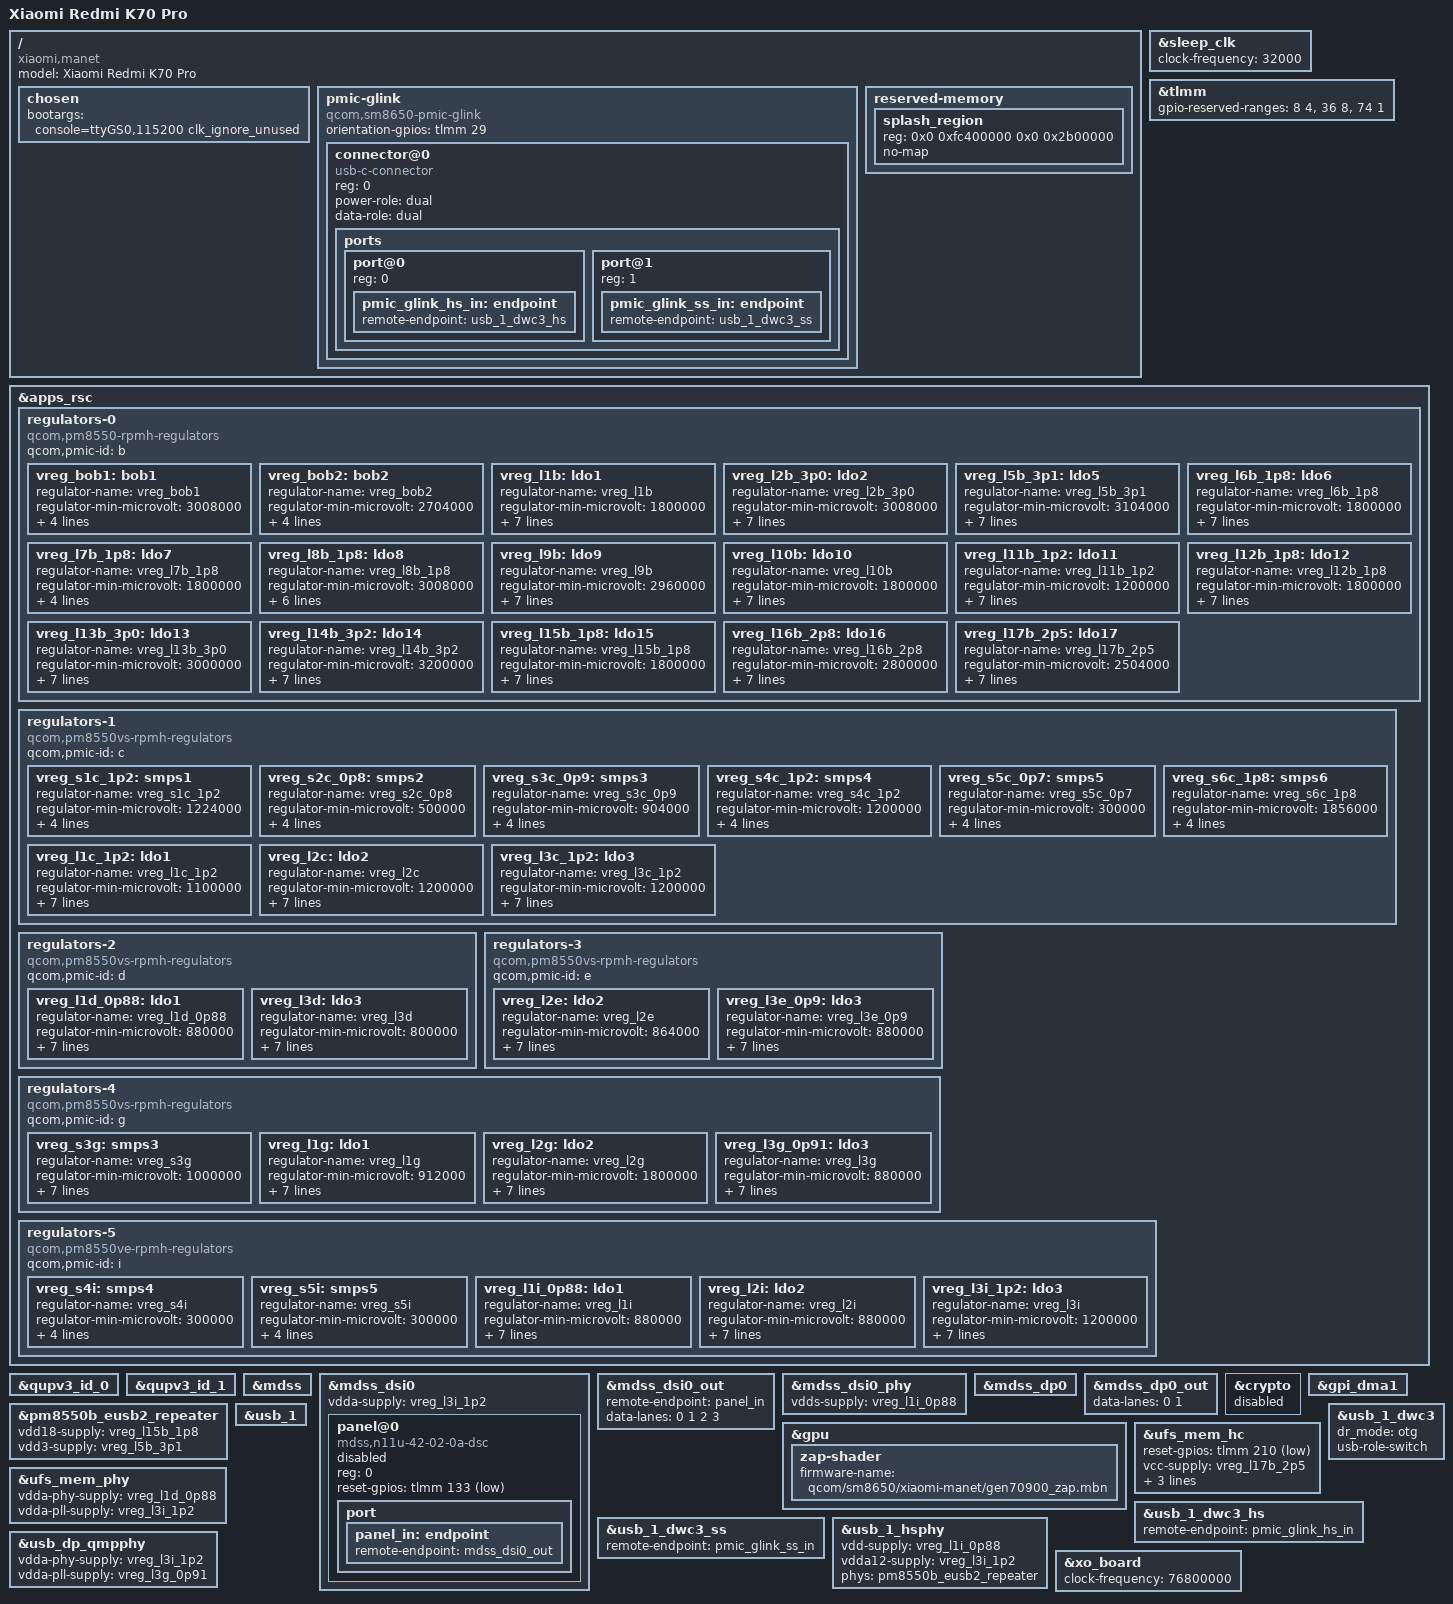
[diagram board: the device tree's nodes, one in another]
// SPDX-License-Identifier: BSD-3-Clause
/*
 * Copyright (c) 2024, Igor Belwon <ibelwon@protonmail.com>
 */

/dts-v1/;

#include <dt-bindings/pinctrl/qcom,pmic-gpio.h>
#include <dt-bindings/regulator/qcom,rpmh-regulator.h>
#include "sm8650.dtsi"
#include "pm8550.dtsi"
#include "pm8550b.dtsi"
#define PMK8550VE_SID 8
#include "pm8550ve.dtsi"
#include "pm8550vs.dtsi"
#include "pmk8550.dtsi"
#include "pmr735d_a.dtsi"

/delete-node/ &hwfence_shbuf;
/delete-node/ &rmtfs_mem;

/ {
        model = "Xiaomi Redmi K70 Pro";
        compatible = "xiaomi,manet", "qcom,sm8650";

        chosen {
                #address-cells = <2>;
                #size-cells = <2>;
                ranges;

                bootargs = "console=ttyGS0,115200 clk_ignore_unused";
        };

	pmic-glink {
		compatible = "qcom,sm8650-pmic-glink",
			     "qcom,sm8550-pmic-glink",
			     "qcom,pmic-glink";
		#address-cells = <1>;
		#size-cells = <0>;
		orientation-gpios = <&tlmm 29 GPIO_ACTIVE_HIGH>;

		connector@0 {
			compatible = "usb-c-connector";
			reg = <0>;

			power-role = "dual";
			data-role = "dual";

			ports {
				#address-cells = <1>;
				#size-cells = <0>;

				port@0 {
					reg = <0>;

					pmic_glink_hs_in: endpoint {
						remote-endpoint = <&usb_1_dwc3_hs>;
					};
				};

				port@1 {
					reg = <1>;

					pmic_glink_ss_in: endpoint {
						remote-endpoint = <&usb_1_dwc3_ss>;
					};
				};
			};
		};
	};

        reserved-memory {
		/* Hack for simplefb */
                splash_region {
                    reg = <0x0 0xfc400000 0x0 0x2b00000>;
                    no-map;
                };
        };
};

&sleep_clk {
	clock-frequency = <32000>;
};

&tlmm {
	gpio-reserved-ranges = <8 4>, <36 8>, <74 1>;
};

&apps_rsc {
	regulators-0 {
		compatible = "qcom,pm8550-rpmh-regulators";
		qcom,pmic-id = "b";

		vreg_bob1: bob1 {
			regulator-name = "vreg_bob1";
			regulator-min-microvolt = <3008000>;
			regulator-max-microvolt = <3960000>;
			regulator-initial-mode = <RPMH_REGULATOR_MODE_HPM>;
			regulator-always-on;
		};

		vreg_bob2: bob2 {
			regulator-name = "vreg_bob2";
			regulator-min-microvolt = <2704000>;
			regulator-max-microvolt = <3296000>;
			regulator-initial-mode = <RPMH_REGULATOR_MODE_HPM>;
			regulator-always-on;
		};

		vreg_l1b: ldo1 {
			regulator-name = "vreg_l1b";
			regulator-min-microvolt = <1800000>;
			regulator-max-microvolt = <1800000>;
			regulator-initial-mode = <RPMH_REGULATOR_MODE_HPM>;
			regulator-allow-set-load;
			regulator-allowed-modes = <RPMH_REGULATOR_MODE_LPM
						   RPMH_REGULATOR_MODE_HPM>;
			regulator-always-on;
		};

		vreg_l2b_3p0: ldo2 {
			regulator-name = "vreg_l2b_3p0";
			regulator-min-microvolt = <3008000>;
			regulator-max-microvolt = <3008000>;
			regulator-initial-mode = <RPMH_REGULATOR_MODE_HPM>;
			regulator-allow-set-load;
			regulator-allowed-modes = <RPMH_REGULATOR_MODE_LPM
						   RPMH_REGULATOR_MODE_HPM>;
			regulator-always-on;
		};

		vreg_l5b_3p1: ldo5 {
			regulator-name = "vreg_l5b_3p1";
			regulator-min-microvolt = <3104000>;
			regulator-max-microvolt = <3104000>;
			regulator-initial-mode = <RPMH_REGULATOR_MODE_HPM>;
			regulator-allow-set-load;
			regulator-allowed-modes = <RPMH_REGULATOR_MODE_LPM
						   RPMH_REGULATOR_MODE_HPM>;
			regulator-always-on;
		};

		vreg_l6b_1p8: ldo6 {
			regulator-name = "vreg_l6b_1p8";
			regulator-min-microvolt = <1800000>;
			regulator-max-microvolt = <3008000>;
			regulator-initial-mode = <RPMH_REGULATOR_MODE_HPM>;
			regulator-allow-set-load;
			regulator-allowed-modes = <RPMH_REGULATOR_MODE_LPM
						   RPMH_REGULATOR_MODE_HPM>;
			regulator-always-on;
		};

		vreg_l7b_1p8: ldo7 {
			regulator-name = "vreg_l7b_1p8";
			regulator-min-microvolt = <1800000>;
			regulator-max-microvolt = <3008000>;
			regulator-initial-mode = <RPMH_REGULATOR_MODE_HPM>;
			regulator-always-on;
		};

		vreg_l8b_1p8: ldo8 {
			regulator-name = "vreg_l8b_1p8";
			regulator-min-microvolt = <3008000>;
			regulator-max-microvolt = <3008000>;
			regulator-initial-mode = <RPMH_REGULATOR_MODE_HPM>;
			regulator-allow-set-load;
			regulator-allowed-modes = <RPMH_REGULATOR_MODE_LPM
						   RPMH_REGULATOR_MODE_HPM>;
		};

		vreg_l9b: ldo9 {
			regulator-name = "vreg_l9b";
			regulator-min-microvolt = <2960000>;
			regulator-max-microvolt = <3008000>;
			regulator-initial-mode = <RPMH_REGULATOR_MODE_HPM>;
			regulator-allow-set-load;
			regulator-allowed-modes = <RPMH_REGULATOR_MODE_LPM
						   RPMH_REGULATOR_MODE_HPM>;
			regulator-always-on;
		};

		vreg_l10b: ldo10 {
			regulator-name = "vreg_l10b";
			regulator-min-microvolt = <1800000>;
			regulator-max-microvolt = <1800000>;
			regulator-initial-mode = <RPMH_REGULATOR_MODE_HPM>;
			regulator-allow-set-load;
			regulator-allowed-modes = <RPMH_REGULATOR_MODE_LPM
						   RPMH_REGULATOR_MODE_HPM>;
			regulator-always-on;
		};

		vreg_l11b_1p2: ldo11 {
			regulator-name = "vreg_l11b_1p2";
			regulator-min-microvolt = <1200000>;
			regulator-max-microvolt = <1200000>;
			regulator-initial-mode = <RPMH_REGULATOR_MODE_HPM>;
			regulator-allow-set-load;
			regulator-allowed-modes = <RPMH_REGULATOR_MODE_LPM
						   RPMH_REGULATOR_MODE_HPM>;
			regulator-always-on;
		};

		vreg_l12b_1p8: ldo12 {
			regulator-name = "vreg_l12b_1p8";
			regulator-min-microvolt = <1800000>;
			regulator-max-microvolt = <1800000>;
			regulator-initial-mode = <RPMH_REGULATOR_MODE_HPM>;
			regulator-allow-set-load;
			regulator-allowed-modes = <RPMH_REGULATOR_MODE_LPM
						   RPMH_REGULATOR_MODE_HPM>;
			regulator-always-on;
		};

		vreg_l13b_3p0: ldo13 {
			regulator-name = "vreg_l13b_3p0";
			regulator-min-microvolt = <3000000>;
			regulator-max-microvolt = <3000000>;
			regulator-initial-mode = <RPMH_REGULATOR_MODE_HPM>;
			regulator-allow-set-load;
			regulator-allowed-modes = <RPMH_REGULATOR_MODE_LPM
						   RPMH_REGULATOR_MODE_HPM>;
			regulator-always-on;
		};

		vreg_l14b_3p2: ldo14 {
			regulator-name = "vreg_l14b_3p2";
			regulator-min-microvolt = <3200000>;
			regulator-max-microvolt = <3200000>;
			regulator-initial-mode = <RPMH_REGULATOR_MODE_HPM>;
			regulator-allow-set-load;
			regulator-allowed-modes = <RPMH_REGULATOR_MODE_LPM
						   RPMH_REGULATOR_MODE_HPM>;
			regulator-always-on;
		};

		vreg_l15b_1p8: ldo15 {
			regulator-name = "vreg_l15b_1p8";
			regulator-min-microvolt = <1800000>;
			regulator-max-microvolt = <1800000>;
			regulator-initial-mode = <RPMH_REGULATOR_MODE_HPM>;
			regulator-allow-set-load;
			regulator-allowed-modes = <RPMH_REGULATOR_MODE_LPM
						   RPMH_REGULATOR_MODE_HPM>;
			regulator-always-on;
		};

		vreg_l16b_2p8: ldo16 {
			regulator-name = "vreg_l16b_2p8";
			regulator-min-microvolt = <2800000>;
			regulator-max-microvolt = <3008000>;
			regulator-initial-mode = <RPMH_REGULATOR_MODE_HPM>;
			regulator-allow-set-load;
			regulator-allowed-modes = <RPMH_REGULATOR_MODE_LPM
						   RPMH_REGULATOR_MODE_HPM>;
			regulator-always-on;
		};

		vreg_l17b_2p5: ldo17 {
			regulator-name = "vreg_l17b_2p5";
			regulator-min-microvolt = <2504000>;
			regulator-max-microvolt = <2504000>;
			regulator-initial-mode = <RPMH_REGULATOR_MODE_HPM>;
			regulator-allow-set-load;
			regulator-allowed-modes = <RPMH_REGULATOR_MODE_LPM
						   RPMH_REGULATOR_MODE_HPM>;
			regulator-always-on;
		};
	};

	regulators-1 {
		compatible = "qcom,pm8550vs-rpmh-regulators";
		qcom,pmic-id = "c";

		vreg_s1c_1p2: smps1 {
			regulator-name = "vreg_s1c_1p2";
			regulator-min-microvolt = <1224000>;
			regulator-max-microvolt = <1348000>;
			regulator-initial-mode = <RPMH_REGULATOR_MODE_HPM>;
			regulator-always-on;
		};

		vreg_s2c_0p8: smps2 {
			regulator-name = "vreg_s2c_0p8";
			regulator-min-microvolt = <500000>;
			regulator-max-microvolt = <1036000>;
			regulator-initial-mode = <RPMH_REGULATOR_MODE_HPM>;
			regulator-always-on;
		};

		vreg_s3c_0p9: smps3 {
			regulator-name = "vreg_s3c_0p9";
			regulator-min-microvolt = <904000>;
			regulator-max-microvolt = <1064000>;
			regulator-initial-mode = <RPMH_REGULATOR_MODE_HPM>;
			regulator-always-on;
		};

		vreg_s4c_1p2: smps4 {
			regulator-name = "vreg_s4c_1p2";
			regulator-min-microvolt = <1200000>;
			regulator-max-microvolt = <1280000>;
			regulator-initial-mode = <RPMH_REGULATOR_MODE_HPM>;
			regulator-always-on;
		};

		vreg_s5c_0p7: smps5 {
			regulator-name = "vreg_s5c_0p7";
			regulator-min-microvolt = <300000>;
			regulator-max-microvolt = <900000>;
			regulator-initial-mode = <RPMH_REGULATOR_MODE_HPM>;
			regulator-always-on;
		};

		vreg_s6c_1p8: smps6 {
			regulator-name = "vreg_s6c_1p8";
			regulator-min-microvolt = <1856000>;
			regulator-max-microvolt = <2000000>;
			regulator-initial-mode = <RPMH_REGULATOR_MODE_HPM>;
			regulator-always-on;
		};

		vreg_l1c_1p2: ldo1 {
			regulator-name = "vreg_l1c_1p2";
			regulator-min-microvolt = <1100000>;
			regulator-max-microvolt = <1200000>;
			regulator-initial-mode = <RPMH_REGULATOR_MODE_HPM>;
			regulator-allow-set-load;
			regulator-allowed-modes = <RPMH_REGULATOR_MODE_LPM
						   RPMH_REGULATOR_MODE_HPM>;
			regulator-always-on;
		};

		vreg_l2c: ldo2 {
			regulator-name = "vreg_l2c";
			regulator-min-microvolt = <1200000>;
			regulator-max-microvolt = <1200000>;
			regulator-initial-mode = <RPMH_REGULATOR_MODE_HPM>;
			regulator-allow-set-load;
			regulator-allowed-modes = <RPMH_REGULATOR_MODE_LPM
						   RPMH_REGULATOR_MODE_HPM>;
			regulator-always-on;
		};

		vreg_l3c_1p2: ldo3 {
			regulator-name = "vreg_l3c_1p2";
			regulator-min-microvolt = <1200000>;
			regulator-max-microvolt = <1200000>;
			regulator-initial-mode = <RPMH_REGULATOR_MODE_HPM>;
			regulator-allow-set-load;
			regulator-allowed-modes = <RPMH_REGULATOR_MODE_LPM
						   RPMH_REGULATOR_MODE_HPM>;
			regulator-always-on;
		};
	};

	regulators-2 {
		compatible = "qcom,pm8550vs-rpmh-regulators";
		qcom,pmic-id = "d";

		vreg_l1d_0p88: ldo1 {
			regulator-name = "vreg_l1d_0p88";
			regulator-min-microvolt = <880000>;
			regulator-max-microvolt = <920000>;
			regulator-initial-mode = <RPMH_REGULATOR_MODE_HPM>;
			regulator-allow-set-load;
			regulator-allowed-modes = <RPMH_REGULATOR_MODE_LPM
						   RPMH_REGULATOR_MODE_HPM>;
			regulator-always-on;
		};

		vreg_l3d: ldo3 {
			regulator-name = "vreg_l3d";
			regulator-min-microvolt = <800000>;
			regulator-max-microvolt = <900000>;
			regulator-initial-mode = <RPMH_REGULATOR_MODE_HPM>;
			regulator-allow-set-load;
			regulator-allowed-modes = <RPMH_REGULATOR_MODE_LPM
						   RPMH_REGULATOR_MODE_HPM>;
			regulator-always-on;
		};
	};

	regulators-3 {
		compatible = "qcom,pm8550vs-rpmh-regulators";
		qcom,pmic-id = "e";

		vreg_l2e: ldo2 {
			regulator-name = "vreg_l2e";
			regulator-min-microvolt = <864000>;
			regulator-max-microvolt = <972000>;
			regulator-initial-mode = <RPMH_REGULATOR_MODE_HPM>;
			regulator-allow-set-load;
			regulator-allowed-modes = <RPMH_REGULATOR_MODE_LPM
						   RPMH_REGULATOR_MODE_HPM>;
			regulator-always-on;
		};

		vreg_l3e_0p9: ldo3 {
			regulator-name = "vreg_l3e_0p9";
			regulator-min-microvolt = <880000>;
			regulator-max-microvolt = <920000>;
			regulator-initial-mode = <RPMH_REGULATOR_MODE_HPM>;
			regulator-allow-set-load;
			regulator-allowed-modes = <RPMH_REGULATOR_MODE_LPM
						   RPMH_REGULATOR_MODE_HPM>;
			regulator-always-on;
		};
	};

	regulators-4 {
		compatible = "qcom,pm8550vs-rpmh-regulators";
		qcom,pmic-id = "g";

		vreg_s3g: smps3 {
			regulator-name = "vreg_s3g";
			regulator-min-microvolt = <1000000>;
			regulator-max-microvolt = <1100000>;
			regulator-initial-mode = <RPMH_REGULATOR_MODE_HPM>;
			regulator-allow-set-load;
			regulator-allowed-modes = <RPMH_REGULATOR_MODE_LPM
						   RPMH_REGULATOR_MODE_HPM>;
			regulator-always-on;
		};

		vreg_l1g: ldo1 {
			regulator-name = "vreg_l1g";
			regulator-min-microvolt = <912000>;
			regulator-max-microvolt = <920000>;
			regulator-initial-mode = <RPMH_REGULATOR_MODE_HPM>;
			regulator-allow-set-load;
			regulator-allowed-modes = <RPMH_REGULATOR_MODE_LPM
						   RPMH_REGULATOR_MODE_HPM>;
			regulator-always-on;
		};

		vreg_l2g: ldo2 {
			regulator-name = "vreg_l2g";
			regulator-min-microvolt = <1800000>;
			regulator-max-microvolt = <1800000>;
			regulator-initial-mode = <RPMH_REGULATOR_MODE_HPM>;
			regulator-allow-set-load;
			regulator-allowed-modes = <RPMH_REGULATOR_MODE_LPM
						   RPMH_REGULATOR_MODE_HPM>;
			regulator-always-on;
		};

		vreg_l3g_0p91: ldo3 {
			regulator-name = "vreg_l3g";
			regulator-min-microvolt = <880000>;
			regulator-max-microvolt = <912000>;
			regulator-initial-mode = <RPMH_REGULATOR_MODE_HPM>;
			regulator-allow-set-load;
			regulator-allowed-modes = <RPMH_REGULATOR_MODE_LPM
						   RPMH_REGULATOR_MODE_HPM>;
			regulator-always-on;
		};
	};

	regulators-5 {
		compatible = "qcom,pm8550ve-rpmh-regulators";
		qcom,pmic-id = "i";

		vreg_s4i: smps4 {
			regulator-name = "vreg_s4i";
			regulator-min-microvolt = <300000>;
			regulator-max-microvolt = <1004000>;
			regulator-initial-mode = <RPMH_REGULATOR_MODE_HPM>;
			regulator-always-on;
		};

		vreg_s5i: smps5 {
			regulator-name = "vreg_s5i";
			regulator-min-microvolt = <300000>;
			regulator-max-microvolt = <700000>;
			regulator-initial-mode = <RPMH_REGULATOR_MODE_HPM>;
			regulator-always-on;
		};

		vreg_l1i_0p88: ldo1 {
			regulator-name = "vreg_l1i";
			regulator-min-microvolt = <880000>;
			regulator-max-microvolt = <912000>;
			regulator-initial-mode = <RPMH_REGULATOR_MODE_HPM>;
			regulator-allow-set-load;
			regulator-allowed-modes = <RPMH_REGULATOR_MODE_LPM
						   RPMH_REGULATOR_MODE_HPM>;
			regulator-always-on;
		};

		vreg_l2i: ldo2 {
			regulator-name = "vreg_l2i";
			regulator-min-microvolt = <880000>;
			regulator-max-microvolt = <912000>;
			regulator-initial-mode = <RPMH_REGULATOR_MODE_HPM>;
			regulator-allow-set-load;
			regulator-allowed-modes = <RPMH_REGULATOR_MODE_LPM
						   RPMH_REGULATOR_MODE_HPM>;
			regulator-always-on;
		};

		vreg_l3i_1p2: ldo3 {
			regulator-name = "vreg_l3i";
			regulator-min-microvolt = <1200000>;
			regulator-max-microvolt = <1200000>;
			regulator-initial-mode = <RPMH_REGULATOR_MODE_HPM>;
			regulator-allow-set-load;
			regulator-allowed-modes = <RPMH_REGULATOR_MODE_LPM
						   RPMH_REGULATOR_MODE_HPM>;
			regulator-always-on;
		};
	};
};

&qupv3_id_0 {
	status = "okay";
};

&qupv3_id_1 {
	status = "okay";
};

&mdss {
	status = "okay";
};

&mdss_dsi0 {
	vdda-supply = <&vreg_l3i_1p2>;

	status = "okay";
	panel@0 {
		compatible = "mdss,n11u-42-02-0a-dsc";
		reg = <0>;
		status = "disabled";
		reset-gpios = <&tlmm 133 GPIO_ACTIVE_LOW>;

		port {
			panel_in: endpoint {
				remote-endpoint = <&mdss_dsi0_out>;
			};
		};
	};
};

&mdss_dsi0_out {
	remote-endpoint = <&panel_in>;
	data-lanes = <0 1 2 3>;
};

&mdss_dsi0_phy {
	vdds-supply = <&vreg_l1i_0p88>;

	status = "okay";
};

&mdss_dp0 {
	status = "okay";
};

&mdss_dp0_out {
	data-lanes = <0 1>;
};

&crypto {
	status = "disabled";
};

&gpi_dma1 {
	status = "okay";
};

&pm8550b_eusb2_repeater {
	vdd18-supply = <&vreg_l15b_1p8>;
	vdd3-supply = <&vreg_l5b_3p1>;
};

&gpu {
	status = "okay";

	zap-shader {
		firmware-name = "qcom/sm8650/xiaomi-manet/gen70900_zap.mbn";
	};
};

&ufs_mem_hc {
	reset-gpios = <&tlmm 210 GPIO_ACTIVE_LOW>;

	vcc-supply = <&vreg_l17b_2p5>;
	vcc-max-microamp = <1300000>;
	vccq-supply = <&vreg_l1c_1p2>;
	vccq-max-microamp = <1200000>;

	status = "okay";
};

&ufs_mem_phy {
	vdda-phy-supply = <&vreg_l1d_0p88>;
	vdda-pll-supply = <&vreg_l3i_1p2>;

	status = "okay";
};

/*
 * DPAUX -> WCD9395 -> USB_SBU -> USB-C
 * eUSB2 DP/DM -> PM85550HS -> eUSB2 DP/DM -> USB-C
 * USB SS -> USB-C
 */

&usb_1 {
	status = "okay";
};

&usb_1_dwc3 {
	dr_mode = "otg";
	usb-role-switch;
};

&usb_1_dwc3_hs {
	remote-endpoint = <&pmic_glink_hs_in>;
};

&usb_1_dwc3_ss {
	remote-endpoint = <&pmic_glink_ss_in>;
};

&usb_1_hsphy {
	vdd-supply = <&vreg_l1i_0p88>;
	vdda12-supply = <&vreg_l3i_1p2>;

	phys = <&pm8550b_eusb2_repeater>;

	status = "okay";
};

&usb_dp_qmpphy {
	vdda-phy-supply = <&vreg_l3i_1p2>;
	vdda-pll-supply = <&vreg_l3g_0p91>;

	status = "okay";
};

&xo_board {
	clock-frequency = <76800000>;
};
